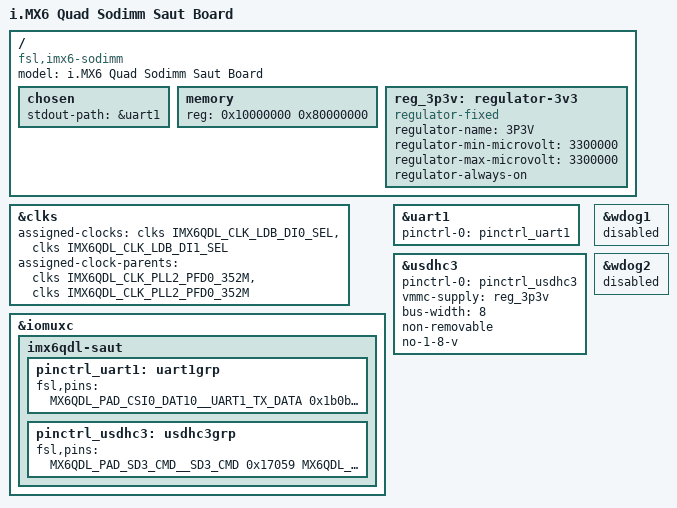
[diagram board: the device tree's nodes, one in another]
// SPDX-License-Identifier: GPL-2.0+
//
// Copyright (C) 2023, Yuriy Zubkov <utlark@ya.ru>
//

/dts-v1/;

#include "imx6q.dtsi"

#include <dt-bindings/clock/imx6qdl-clock.h>

#include <dt-bindings/gpio/gpio.h>
#include <dt-bindings/input/input.h>

/ {
	model = "i.MX6 Quad Sodimm Saut Board";
	compatible = "fsl,imx6-sodimm", "fsl,imx6q";

	chosen {
		stdout-path = &uart1;
	};

	memory: memory {
		reg = <0x10000000 0x80000000>;
	};

	reg_3p3v: regulator-3v3 {
		compatible = "regulator-fixed";
		regulator-name = "3P3V";
		regulator-min-microvolt = <3300000>;
		regulator-max-microvolt = <3300000>;
		regulator-always-on;
	};
};

&clks {
	assigned-clocks = <&clks IMX6QDL_CLK_LDB_DI0_SEL>, <&clks IMX6QDL_CLK_LDB_DI1_SEL>;
	assigned-clock-parents = <&clks IMX6QDL_CLK_PLL2_PFD0_352M>, <&clks IMX6QDL_CLK_PLL2_PFD0_352M>;
};

&iomuxc {
	pinctrl-names = "default";

	imx6qdl-saut {
		pinctrl_uart1: uart1grp {
			fsl,pins = <
				MX6QDL_PAD_CSI0_DAT10__UART1_TX_DATA	0x1b0b1
				MX6QDL_PAD_CSI0_DAT11__UART1_RX_DATA	0x1b0b1
			>;
		};

		pinctrl_usdhc3: usdhc3grp {
			fsl,pins = <
				MX6QDL_PAD_SD3_CMD__SD3_CMD				0x17059
				MX6QDL_PAD_SD3_CLK__SD3_CLK				0x10059
				MX6QDL_PAD_SD3_DAT0__SD3_DATA0			0x17059
				MX6QDL_PAD_SD3_DAT1__SD3_DATA1			0x17059
				MX6QDL_PAD_SD3_DAT2__SD3_DATA2			0x17059
				MX6QDL_PAD_SD3_DAT3__SD3_DATA3			0x17059
				MX6QDL_PAD_SD3_DAT4__SD3_DATA4			0x17059
				MX6QDL_PAD_SD3_DAT5__SD3_DATA5			0x17059
				MX6QDL_PAD_SD3_DAT6__SD3_DATA6			0x17059
				MX6QDL_PAD_SD3_DAT7__SD3_DATA7			0x17059
			>;
		};
	};
};

&uart1 {
	pinctrl-names = "default";
	pinctrl-0 = <&pinctrl_uart1>;
	status = "okay";
};

&usdhc3 {
	pinctrl-names = "default";
	pinctrl-0 = <&pinctrl_usdhc3>;
	vmmc-supply = <&reg_3p3v>;
	bus-width = <8>;
	non-removable;
	no-1-8-v;
	status = "okay";
};

&wdog1 {
	status = "disabled";
};

&wdog2 {
	status = "disabled";
};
